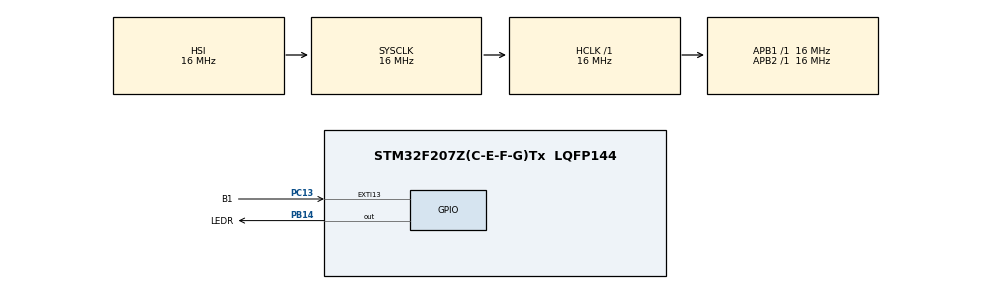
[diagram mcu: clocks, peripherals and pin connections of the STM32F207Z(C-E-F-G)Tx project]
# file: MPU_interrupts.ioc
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Mcu.Family=STM32F2
Mcu.Name=STM32F207Z(C-E-F-G)Tx
Mcu.Package=LQFP144
NVIC.EXTI15_10_IRQn=true\:0\:0\:false\:false\:true\:true\:true
NVIC.PriorityGroup=NVIC_PRIORITYGROUP_4
PB14.GPIO_Label=LEDR
PB14.Signal=GPIO_Output
PC13.GPIO_Label=B1
PC13.Signal=GPXTI13
ProjectManager.HeapSize=0x200
ProjectManager.StackSize=0x400
ProjectManager.TargetToolchain=STM32CubeIDE
RCC.48MHZClocksFreq_Value=48000000
RCC.AHBFreq_Value=16000000
RCC.APB1Freq_Value=16000000
RCC.APB2Freq_Value=16000000
RCC.CortexFreq_Value=16000000
RCC.HSE_VALUE=25000000
RCC.HSI_VALUE=16000000
RCC.LSE_VALUE=32768
RCC.SYSCLKFreq_VALUE=16000000
RCC.VCOOutputFreq_Value=192000000
board=custom

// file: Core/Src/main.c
/* USER CODE BEGIN Header */
/**
  ******************************************************************************
  * @file           : main.c
  * @brief          : Main program body
  * @author         : Michele Grisafi
  ******************************************************************************
  * @attention
  * This code is based on an STMicroelectronics demo application.
  * <h2><center>&copy; Copyright (c) 2021 STMicroelectronics.
  * All rights reserved.</center></h2>
  *
  * This software component is licensed by ST under BSD 3-Clause license,
  * the "License"; You may not use this file except in compliance with the
  * License. You may obtain a copy of the License at:
  *                        opensource.org/licenses/BSD-3-Clause
  *
  ******************************************************************************
  */
/* USER CODE END Header */
#include "main.h"

/* USER CODE BEGIN Includes */
#include "maliciousLibrary.h"
/* USER CODE END Includes */

void SystemClock_Config(void);
static void MX_GPIO_Init(void);

/* USER CODE BEGIN 0 */
void setupMPU(){
	//Define variables to be used in the MPU configuration
	unsigned long unprivilegedRX = ARM_MPU_RASR(0UL,ARM_MPU_AP_URO,1UL,0UL,0UL,0UL,0x00UL,ARM_MPU_REGION_SIZE_512MB) | ARM_MPU_REGION_SIZE_512MB<<1 | 1UL;
	unsigned long unprivilegedRW = ARM_MPU_RASR(1UL,ARM_MPU_AP_FULL,1UL,0UL,0UL,0UL,0x00UL,ARM_MPU_REGION_SIZE_512MB) | ARM_MPU_REGION_SIZE_512MB<<1 | 1UL;
	unsigned long unprivilegdR = ARM_MPU_RASR(1UL,ARM_MPU_AP_RO,1UL,0UL,0UL,0UL,0x00UL,ARM_MPU_REGION_SIZE_32B) | ARM_MPU_REGION_SIZE_32B<<1 | 1UL;
	unsigned long unprivilegedNone = ARM_MPU_RASR(1UL,ARM_MPU_AP_NONE,1UL,0UL,0UL,0UL,0x00UL,ARM_MPU_REGION_SIZE_128B) | ARM_MPU_REGION_SIZE_128B<<1 | 1UL;

	//FLASH as RX
	ARM_MPU_SetRegionEx(1UL, 0x00000000UL, unprivilegedRX);

	//RAM as RW
	ARM_MPU_SetRegionEx(2UL, 0x20000000UL, unprivilegedRW);

	//Small segment in RAM as R
	ARM_MPU_SetRegionEx(3UL, 0x20004000UL, unprivilegdR);

	//Protect access to LED pin
	ARM_MPU_SetRegionEx(4UL, 0x40020400UL, unprivilegedNone);

	//Enable the MPU
	ARM_MPU_Enable(0x05);

}
/* USER CODE END 0 */

int main(void)
{

  /* MCU Configuration--------------------------------------------------------*/

  /* Reset of all peripherals, Initializes the Flash interface and the Systick. */
  HAL_Init();

  /* Configure the system clock */
  SystemClock_Config();

  /* Initialize all configured peripherals */
  MX_GPIO_Init();
  /* USER CODE BEGIN 2 */
  setupMPU();

  //Lower privileges
  __asm("MOV R0, #01");
  __asm("MSR CONTROL, R0");

  //This access would trigger a violation! --> commented out
  //HAL_GPIO_TogglePin(GPIOB, GPIO_PIN_14);

  /* USER CODE END 2 */

  /* Infinite loop */
  while (1)
  {
	//performTask();
  }
}

void SystemClock_Config(void)
{
  RCC_OscInitTypeDef RCC_OscInitStruct = {0};
  RCC_ClkInitTypeDef RCC_ClkInitStruct = {0};

  /** Initializes the RCC Oscillators according to the specified parameters
  * in the RCC_OscInitTypeDef structure.
  */
  RCC_OscInitStruct.OscillatorType = RCC_OSCILLATORTYPE_HSI;
  RCC_OscInitStruct.HSIState = RCC_HSI_ON;
  RCC_OscInitStruct.HSICalibrationValue = RCC_HSICALIBRATION_DEFAULT;
  RCC_OscInitStruct.PLL.PLLState = RCC_PLL_NONE;
  if (HAL_RCC_OscConfig(&RCC_OscInitStruct) != HAL_OK)
  {
    Error_Handler();
  }
  /** Initializes the CPU, AHB and APB buses clocks
  */
  RCC_ClkInitStruct.ClockType = RCC_CLOCKTYPE_HCLK|RCC_CLOCKTYPE_SYSCLK
                              |RCC_CLOCKTYPE_PCLK1|RCC_CLOCKTYPE_PCLK2;
  RCC_ClkInitStruct.SYSCLKSource = RCC_SYSCLKSOURCE_HSI;
  RCC_ClkInitStruct.AHBCLKDivider = RCC_SYSCLK_DIV1;
  RCC_ClkInitStruct.APB1CLKDivider = RCC_HCLK_DIV1;
  RCC_ClkInitStruct.APB2CLKDivider = RCC_HCLK_DIV1;

  if (HAL_RCC_ClockConfig(&RCC_ClkInitStruct, FLASH_LATENCY_0) != HAL_OK)
  {
    Error_Handler();
  }
}

static void MX_GPIO_Init(void)
{
  GPIO_InitTypeDef GPIO_InitStruct = {0};

  /* GPIO Ports Clock Enable */
  __HAL_RCC_GPIOC_CLK_ENABLE();
  __HAL_RCC_GPIOB_CLK_ENABLE();

  /*Configure GPIO pin Output Level */
  HAL_GPIO_WritePin(LEDR_GPIO_Port, LEDR_Pin, GPIO_PIN_RESET);

  /*Configure GPIO pin : B1_Pin */
  GPIO_InitStruct.Pin = B1_Pin;
  GPIO_InitStruct.Mode = GPIO_MODE_IT_RISING;
  GPIO_InitStruct.Pull = GPIO_NOPULL;
  HAL_GPIO_Init(B1_GPIO_Port, &GPIO_InitStruct);

  /*Configure GPIO pin : LEDR_Pin */
  GPIO_InitStruct.Pin = LEDR_Pin;
  GPIO_InitStruct.Mode = GPIO_MODE_OUTPUT_PP;
  GPIO_InitStruct.Pull = GPIO_NOPULL;
  GPIO_InitStruct.Speed = GPIO_SPEED_FREQ_LOW;
  HAL_GPIO_Init(LEDR_GPIO_Port, &GPIO_InitStruct);

  /* EXTI interrupt init*/
  HAL_NVIC_SetPriority(EXTI15_10_IRQn, 0, 0);
  HAL_NVIC_EnableIRQ(EXTI15_10_IRQn);

}

/* USER CODE BEGIN 4 */
void HAL_GPIO_EXTI_Callback(uint16_t GPIO_Pin){
	if (GPIO_Pin == B1_Pin){
		performTask();
	}
}
/* USER CODE END 4 */

void Error_Handler(void)
{
  __disable_irq();
  while (1)
  {
  }
}

/************************ (C) COPYRIGHT STMicroelectronics *****END OF FILE****/
